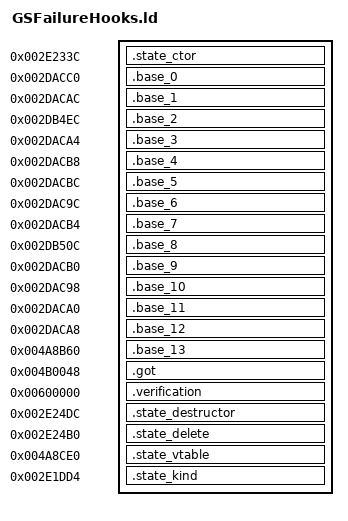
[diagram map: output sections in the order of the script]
OUTPUT_FORMAT("elf32-littlearm")
OUTPUT_ARCH(arm)
INCLUDE build/matches/state-hooks-gsfailure/retail-symbols.ld
_ZdlPv = 0x001c42b0;
SECTIONS
{
    .state_ctor 0x002e233c : { *state-hooks-gsfailure.o(.text._ZN9GSFailureC1Ev) }
    .base_0 0x002dacc0 : { *state-hooks-gsfailure.o(.gnu.linkonce.t._ZN9StateBase8isKindOfEi .text._ZN9StateBase8isKindOfEi .gnu.linkonce.d.rel.ro._ZN9StateBase8isKindOfEi .data.rel.ro._ZN9StateBase8isKindOfEi) }
    .base_1 0x002dacac : { *state-hooks-gsfailure.o(.gnu.linkonce.t._ZN9StateBase4drawEPK12StateMachine .text._ZN9StateBase4drawEPK12StateMachine .gnu.linkonce.d.rel.ro._ZN9StateBase4drawEPK12StateMachine .data.rel.ro._ZN9StateBase4drawEPK12StateMachine) }
    .base_2 0x002db4ec : { *state-hooks-gsfailure.o(.gnu.linkonce.t._ZN9StateBaseD0Ev .text._ZN9StateBaseD0Ev .gnu.linkonce.d.rel.ro._ZN9StateBaseD0Ev .data.rel.ro._ZN9StateBaseD0Ev) }
    .base_3 0x002daca4 : { *state-hooks-gsfailure.o(.gnu.linkonce.t._ZN9StateBase6resumeEPK12StateMachine .text._ZN9StateBase6resumeEPK12StateMachine .gnu.linkonce.d.rel.ro._ZN9StateBase6resumeEPK12StateMachine .data.rel.ro._ZN9StateBase6resumeEPK12StateMachine) }
    .base_4 0x002dacb8 : { *state-hooks-gsfailure.o(.gnu.linkonce.t._ZN9StateBase6wakeupEPK12StateMachine .text._ZN9StateBase6wakeupEPK12StateMachine .gnu.linkonce.d.rel.ro._ZN9StateBase6wakeupEPK12StateMachine .data.rel.ro._ZN9StateBase6wakeupEPK12StateMachine) }
    .base_5 0x002dacbc : { *state-hooks-gsfailure.o(.gnu.linkonce.t._ZN9StateBase10isDrawableEv .text._ZN9StateBase10isDrawableEv .gnu.linkonce.d.rel.ro._ZN9StateBase10isDrawableEv .data.rel.ro._ZN9StateBase10isDrawableEv) }
    .base_6 0x002dac9c : { *state-hooks-gsfailure.o(.gnu.linkonce.t._ZN9StateBase4dtorEPK12StateMachine .text._ZN9StateBase4dtorEPK12StateMachine .gnu.linkonce.d.rel.ro._ZN9StateBase4dtorEPK12StateMachine .data.rel.ro._ZN9StateBase4dtorEPK12StateMachine) }
    .base_7 0x002dacb4 : { *state-hooks-gsfailure.o(.gnu.linkonce.t._ZN9StateBase5sleepEPK12StateMachine .text._ZN9StateBase5sleepEPK12StateMachine .gnu.linkonce.d.rel.ro._ZN9StateBase5sleepEPK12StateMachine .data.rel.ro._ZN9StateBase5sleepEPK12StateMachine) }
    .base_8 0x002db50c : { *state-hooks-gsfailure.o(.gnu.linkonce.t._ZN9StateBaseD1Ev .text._ZN9StateBaseD1Ev .gnu.linkonce.d.rel.ro._ZN9StateBaseD1Ev .data.rel.ro._ZN9StateBaseD1Ev) }
    .base_9 0x002dacb0 : { *state-hooks-gsfailure.o(.gnu.linkonce.t._ZN9StateBase6draw2dEPK12StateMachine .text._ZN9StateBase6draw2dEPK12StateMachine .gnu.linkonce.d.rel.ro._ZN9StateBase6draw2dEPK12StateMachine .data.rel.ro._ZN9StateBase6draw2dEPK12StateMachine) }
    .base_10 0x002dac98 : { *state-hooks-gsfailure.o(.gnu.linkonce.t._ZN9StateBase4ctorEPK12StateMachine .text._ZN9StateBase4ctorEPK12StateMachine .gnu.linkonce.d.rel.ro._ZN9StateBase4ctorEPK12StateMachine .data.rel.ro._ZN9StateBase4ctorEPK12StateMachine) }
    .base_11 0x002daca0 : { *state-hooks-gsfailure.o(.gnu.linkonce.t._ZN9StateBase5pauseEPK12StateMachine .text._ZN9StateBase5pauseEPK12StateMachine .gnu.linkonce.d.rel.ro._ZN9StateBase5pauseEPK12StateMachine .data.rel.ro._ZN9StateBase5pauseEPK12StateMachine) }
    .base_12 0x002daca8 : { *state-hooks-gsfailure.o(.gnu.linkonce.t._ZN9StateBase6updateEP12StateMachine .text._ZN9StateBase6updateEP12StateMachine .gnu.linkonce.d.rel.ro._ZN9StateBase6updateEP12StateMachine .data.rel.ro._ZN9StateBase6updateEP12StateMachine) }
    .base_13 0x004a8b60 : { *state-hooks-gsfailure.o(.gnu.linkonce.t._ZTV9StateBase .text._ZTV9StateBase .gnu.linkonce.d.rel.ro._ZTV9StateBase .data.rel.ro._ZTV9StateBase) }
    .got 0x004b0048 : { *(.got.plt) . = 0x360; *(.got) }
    .verification 0x00600000 : { *retail-got.o(.text) }
    .state_destructor 0x002e24dc : { *state-hooks-gsfailure.o(.text._ZN9GSFailureD1Ev) }
    .state_delete 0x002e24b0 : { *state-hooks-gsfailure.o(.text._ZN9GSFailureD0Ev) }
    .state_vtable 0x004a8ce0 : { *state-hooks-gsfailure.o(.data.rel.ro._ZTV9GSFailure .gnu.linkonce.d.rel.ro._ZTV9GSFailure) }
    .state_kind 0x002e1dd4 : { *state-hooks-gsfailure.o(.gnu.linkonce.t._ZN9GSFailure8isKindOfEi .text._ZN9GSFailure8isKindOfEi) }
}
